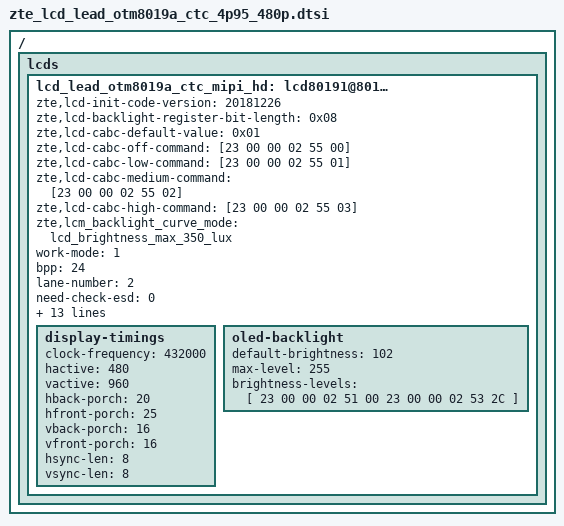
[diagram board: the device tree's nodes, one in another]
/ { lcds {
	lcd_lead_otm8019a_ctc_mipi_hd: lcd80191@80191 {
		zte,lcd-init-code-version = "20181226";
		zte,lcd-backlight-register-bit-length = <0x08>;
		zte,lcd-cabc-default-value = <0x01>;
		zte,lcd-cabc-off-command = [23 00 00 02 55 00];
		zte,lcd-cabc-low-command = [23 00 00 02 55 01];
		zte,lcd-cabc-medium-command = [23 00 00 02 55 02];
		zte,lcd-cabc-high-command = [23 00 00 02 55 03];
		zte,lcm_backlight_curve_mode = "lcd_brightness_max_350_lux";

		work-mode = <1>;
		bpp = <24>;
		lane-number = <2>;

		need-check-esd = <0>;
		esd-timeout = <1000>;
		esd-check-reg = <0x09>;
		esd-return-code = <0x80>;

		fps = <60>;
		width-mm = <56>;
		height-mm = <112>;
		panel-name = "lcd_lead_otm8019a_ctc_mipi_hd";

		power-on-sequence = <
					50  1  2
					50  0  1
					50  1  10
					>;
		power-off-sequence = <
					50  0  120
					>;

		init-data = [
			39 00 00 02 00 00
			39 00 00 04 ff 80 19 01
			39 00 00 02 00 80
			39 00 00 03 ff 80 19
			39 00 00 02 00 90
			39 00 00 02 b3 02
			39 00 00 02 00 92
			39 00 00 02 b3 40
			39 00 00 02 00 a2
			39 00 00 05 b3 01 e0 03 c0
			39 00 00 02 00 a7
			39 00 00 02 b3 04
			39 00 00 02 00 80
			39 00 00 07 c0 00 5f 00 1a 1a 00
			39 00 00 02 00 90
			39 00 00 07 c0 00 15 00 00 00 03
			39 00 00 02 00 a0
			39 00 00 02 c1 e8
			39 00 00 02 00 b4
			39 00 00 02 c0 77
			39 00 00 02 00 80
			39 00 00 07 ce 8b 03 00 8a 03 00
			39 00 00 02 00 a0
			39 00 00 0f ce 38 05 03 c7 00 22 00 38 04 03 c8 00 22 00
			39 00 00 02 00 b0
			39 00 00 0f ce 38 03 03 c9 00 22 00 38 02 03 cb 00 22 00
			39 00 00 02 00 c0
			39 00 00 0f ce 38 09 03 c3 00 22 00 38 08 03 c4 00 22 00
			39 00 00 02 00 d0
			39 00 00 0f ce 38 07 03 c5 00 22 00 38 06 03 c6 00 22 00
			39 00 00 02 00 e0
			39 00 00 09 ce 02 02 00 00 00 00 00 00
			39 00 00 02 00 f0
			39 00 00 03 ce a0 00
			39 00 00 02 00 c0
			39 00 00 0b cf 09 00 01 00 00 00 01 00 20 00
			39 00 00 02 00 c0
			39 00 00 10 cb 15 15 15 15 15 15 00 00 15 00 15 00 00 00 00
			39 00 00 02 00 d0
			39 00 00 10 cb 00 00 00 00 00 00 00 00 00 00 15 00 15 00 00
			39 00 00 02 00 e0
			39 00 00 0b cb 15 15 15 15 15 15 00 00 00 00
			39 00 00 02 00 f0
			39 00 00 0b cb ff 0f 33 00 00 00 cc c0 ff 00
			39 00 00 02 00 80
			39 00 00 0b cc 02 0c 0a 10 0e 00 00 00 21 00
			39 00 00 02 00 90
			39 00 00 10 cc 22 00 00 00 00 00 00 00 00 00 00 00 00 00 00
			39 00 00 02 00 a0
			39 00 00 10 cc 22 00 21 00 00 00 0d 0f 09 0b 01 00 00 00 00
			39 00 00 02 00 b0
			39 00 00 0b cc 00 09 0b 0d 0f 01 00 00 21 00
			39 00 00 02 00 c0
			39 00 00 10 cc 22 00 00 00 00 00 00 00 00 00 00 00 00 00 00
			39 00 00 02 00 d0
			39 00 00 10 cc 22 00 21 00 00 02 10 0e 0c 0a 00 00 00 00 00
			39 00 00 02 00 d0
			39 00 00 03 cf 00 87
			39 00 00 02 00 00
			39 00 00 15 e1 0B 0D 0D 14 21 33 43 80 73 8A 7D 6C 86 72 79 71 6E 65 5B 2B
			39 00 00 02 00 00
			39 00 00 15 e2 0B 0D 0D 14 21 33 43 80 73 8A 7E 6C 85 72 79 71 6E 65 5B 2B
			39 00 00 02 00 80
			39 00 00 03 c1 03 44
			39 00 00 02 00 90
			39 00 00 03 c5 4E 79
			39 00 00 02 00 82
			39 00 00 02 c5 b0
			39 00 00 02 00 00
			39 00 00 03 d8 6F 6F
			39 00 00 02 00 00
			39 00 00 02 d9 5F
			39 00 00 02 00 b1
			39 00 00 02 c5 b9
			39 00 00 02 00 92
			39 00 00 02 c5 01
			39 00 00 02 00 94
			39 00 00 03 c5 66 66
			39 00 00 02 00 89
			39 00 00 02 c4 08
			39 00 00 02 00 a2
			39 00 00 04 c0 00 00 00
			39 00 00 02 00 90
			39 00 00 07 c0 00 13 00 08 00 0c
			39 00 00 02 00 80
			39 00 00 02 c4 30
			39 00 00 02 00 80
			39 00 00 04 c1 03 44 84
			39 00 00 02 00 98
			39 00 00 02 c0 00
			39 00 00 02 00 a9
			39 00 00 02 c0 0a
			39 00 00 02 00 b0
			39 00 00 07 c1 20 00 00 00 02 01
			39 00 00 02 00 e1
			39 00 00 03 c0 40 30
			39 00 00 02 00 a0
			39 00 00 02 c1 e8
			39 00 00 02 00 90
			39 00 00 03 b6 b4 5a
			39 00 00 02 00 83
			39 00 00 02 c5 01
			39 00 00 02 00 b0
			39 00 00 05 ca 0a 20 5f 50
			39 00 00 02 00 c4
			39 00 00 03 c5 00 00
			39 00 00 02 00 ba
			39 00 00 03 f5 00 00
			39 00 00 02 00 00
			39 00 00 02 fb 01
			39 00 00 02 00 00
			39 00 00 04 ff ff ff ff
			39 00 00 02 35 00
			39 00 00 02 51 00
			39 00 00 02 53 24
			39 00 00 02 55 01
			39 00 00 02 5e 03
			23 78 00 02 11 00
			23 01 00 02 29 00
			];
		sleep-in = [
			13 0A 00 01 28
			13 78 00 01 10
			];
		sleep-out = [
			13 78 00 01 11
			13 64 00 01 29
			];

		display-timings {
			clock-frequency = <432000>;
			hactive = <480>;
			vactive = <960>;
			hback-porch = <20>;
			hfront-porch = <25>;
			vback-porch = <16>;
			vfront-porch = <16>;
			hsync-len = <8>;
			vsync-len = <8>;
		};
		oled-backlight {
			default-brightness = <102>;
			max-level = <255>;
			brightness-levels = [
				23 00 00 02 51 00
				23 00 00 02 53 2C
			];
		};
	};
};};

